VERSION ""

NS_ :

BS_:

BU_: XXX

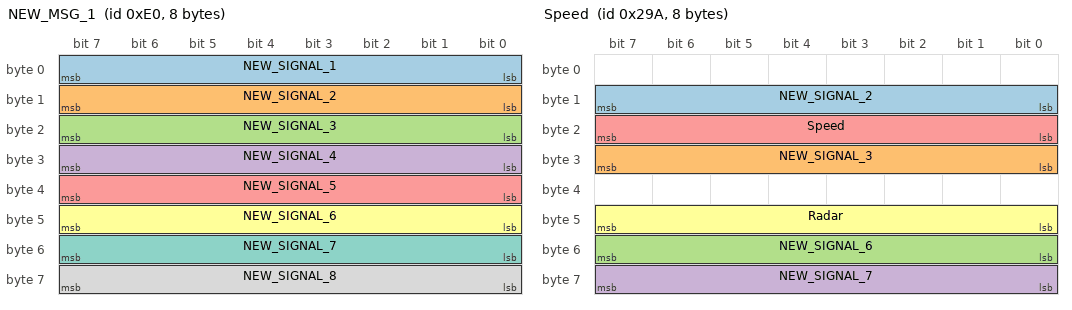
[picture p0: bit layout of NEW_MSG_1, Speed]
BO_ 224 NEW_MSG_1: 8 XXX
 SG_ NEW_SIGNAL_1 : 7|8@0+ (1,0) [0|255] "" XXX
 SG_ NEW_SIGNAL_2 : 15|8@0+ (1,0) [0|255] "" XXX
 SG_ NEW_SIGNAL_3 : 23|8@0+ (1,0) [0|255] "" XXX
 SG_ NEW_SIGNAL_4 : 31|8@0+ (1,0) [0|255] "" XXX
 SG_ NEW_SIGNAL_5 : 39|8@0+ (1,0) [0|255] "" XXX
 SG_ NEW_SIGNAL_6 : 47|8@0+ (1,0) [0|255] "" XXX
 SG_ NEW_SIGNAL_7 : 55|8@0+ (1,0) [0|255] "" XXX
 SG_ NEW_SIGNAL_8 : 63|8@0+ (1,0) [0|255] "" XXX

BO_ 666 Speed: 8 XXX
 SG_ NEW_SIGNAL_2 : 15|8@0+ (1,0) [0|255] "" XXX
 SG_ NEW_SIGNAL_3 : 31|8@0+ (1,0) [0|255] "" XXX
 SG_ NEW_SIGNAL_6 : 55|8@0+ (1,0) [0|255] "" XXX
 SG_ NEW_SIGNAL_7 : 63|8@0+ (1,0) [0|255] "" XXX
 SG_ Speed : 23|8@0+ (1,0) [0|255] "" XXX
 SG_ Radar : 47|8@0+ (1,0) [0|255] "" XXX

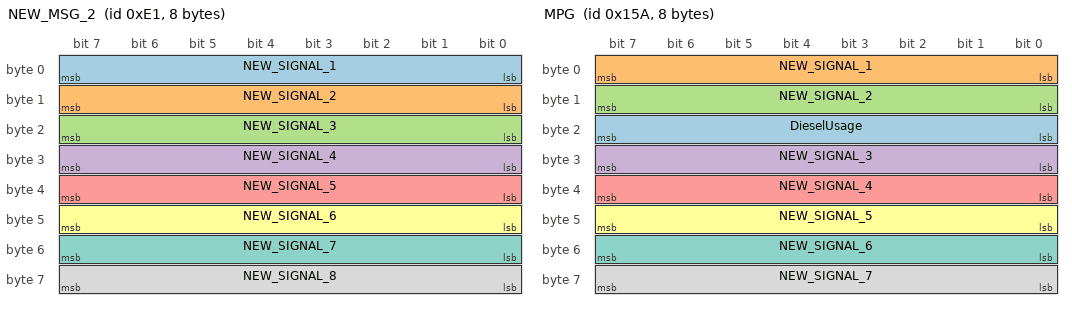
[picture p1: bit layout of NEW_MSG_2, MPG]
BO_ 225 NEW_MSG_2: 8 XXX
 SG_ NEW_SIGNAL_1 : 7|8@0+ (1,0) [0|255] "" XXX
 SG_ NEW_SIGNAL_2 : 15|8@0+ (1,0) [0|255] "" XXX
 SG_ NEW_SIGNAL_3 : 23|8@0+ (1,0) [0|255] "" XXX
 SG_ NEW_SIGNAL_4 : 31|8@0+ (1,0) [0|255] "" XXX
 SG_ NEW_SIGNAL_5 : 39|8@0+ (1,0) [0|255] "" XXX
 SG_ NEW_SIGNAL_6 : 47|8@0+ (1,0) [0|255] "" XXX
 SG_ NEW_SIGNAL_7 : 55|8@0+ (1,0) [0|255] "" XXX
 SG_ NEW_SIGNAL_8 : 63|8@0+ (1,0) [0|255] "" XXX

BO_ 346 MPG: 8 XXX
 SG_ DieselUsage : 23|8@0+ (1,0) [0|255] "" XXX
 SG_ NEW_SIGNAL_1 : 7|8@0+ (1,0) [0|255] "" XXX
 SG_ NEW_SIGNAL_2 : 15|8@0+ (1,0) [0|255] "" XXX
 SG_ NEW_SIGNAL_3 : 31|8@0+ (1,0) [0|255] "" XXX
 SG_ NEW_SIGNAL_4 : 39|8@0+ (1,0) [0|255] "" XXX
 SG_ NEW_SIGNAL_5 : 47|8@0+ (1,0) [0|255] "" XXX
 SG_ NEW_SIGNAL_6 : 55|8@0+ (1,0) [0|255] "" XXX
 SG_ NEW_SIGNAL_7 : 63|8@0+ (1,0) [0|255] "" XXX

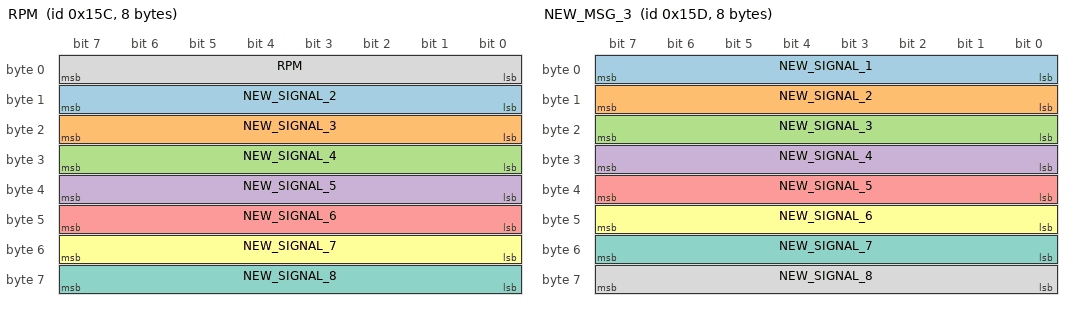
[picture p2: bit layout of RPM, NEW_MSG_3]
BO_ 348 RPM: 8 XXX
 SG_ NEW_SIGNAL_2 : 15|8@0+ (1,0) [0|255] "" XXX
 SG_ NEW_SIGNAL_3 : 23|8@0+ (1,0) [0|255] "" XXX
 SG_ NEW_SIGNAL_4 : 31|8@0+ (1,0) [0|255] "" XXX
 SG_ NEW_SIGNAL_5 : 39|8@0+ (1,0) [0|255] "" XXX
 SG_ NEW_SIGNAL_6 : 47|8@0+ (1,0) [0|255] "" XXX
 SG_ NEW_SIGNAL_7 : 55|8@0+ (1,0) [0|255] "" XXX
 SG_ NEW_SIGNAL_8 : 63|8@0+ (1,0) [0|255] "" XXX
 SG_ RPM : 7|8@0+ (1,0) [0|255] "" XXX

BO_ 349 NEW_MSG_3: 8 XXX
 SG_ NEW_SIGNAL_1 : 7|8@0+ (1,0) [0|255] "" XXX
 SG_ NEW_SIGNAL_2 : 15|8@0+ (1,0) [0|255] "" XXX
 SG_ NEW_SIGNAL_3 : 23|8@0+ (1,0) [0|255] "" XXX
 SG_ NEW_SIGNAL_4 : 31|8@0+ (1,0) [0|255] "" XXX
 SG_ NEW_SIGNAL_5 : 39|8@0+ (1,0) [0|255] "" XXX
 SG_ NEW_SIGNAL_6 : 47|8@0+ (1,0) [0|255] "" XXX
 SG_ NEW_SIGNAL_7 : 55|8@0+ (1,0) [0|255] "" XXX
 SG_ NEW_SIGNAL_8 : 63|8@0+ (1,0) [0|255] "" XXX
